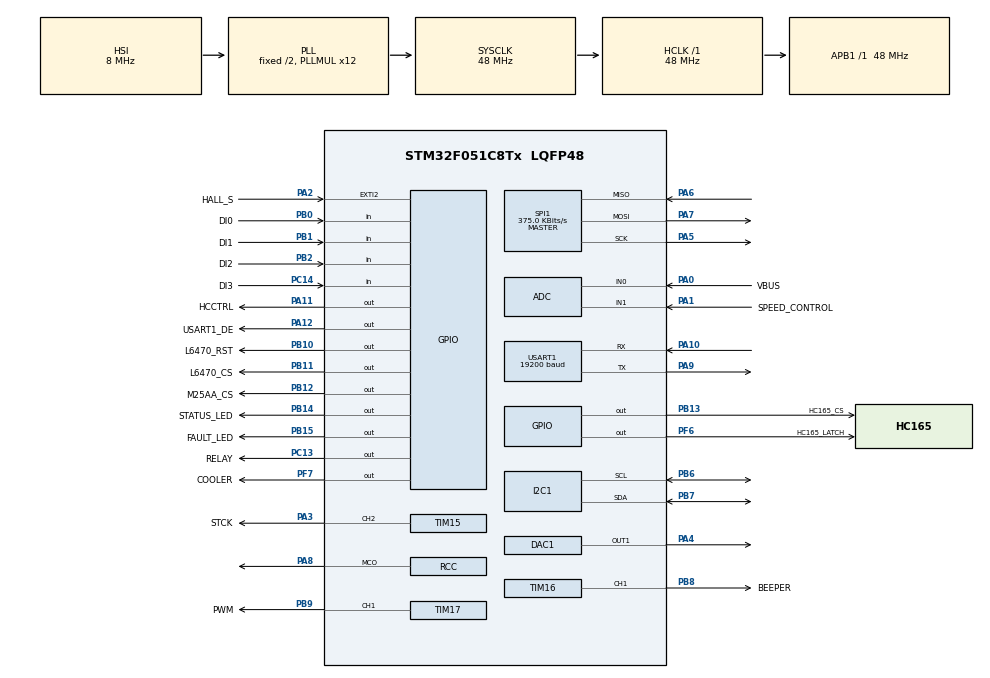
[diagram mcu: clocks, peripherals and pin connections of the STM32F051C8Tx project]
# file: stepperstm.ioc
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ADC.Channel-1\#ChannelRegularConversion=ADC_CHANNEL_1
ADC.Channel-2\#ChannelRegularConversion=ADC_CHANNEL_TEMPSENSOR
ADC.Channel-IN=ADC_CHANNEL_TEMPSENSOR
ADC.Channel-IN1=ADC_CHANNEL_1
ADC.NbrOfConversion=3
ADC.NbrOfConversionFlag=1
ADC.Rank-0\#ChannelRegularConversion=1
ADC.Rank-1\#ChannelRegularConversion=2
ADC.Rank-2\#ChannelRegularConversion=3
ADC.SamplingTime=ADC_SAMPLETIME_13CYCLES_5
ADC.master=1
DAC1.DAC_OutputBuffer-DAC_OUT1=DAC_OUTPUTBUFFER_ENABLE
DAC1.DAC_Trigger-DAC_OUT1=DAC_TRIGGER_NONE
Mcu.Family=STM32F0
Mcu.Name=STM32F051C8Tx
Mcu.Package=LQFP48
Mcu.UserConstants=RS485_DE_HW_ENABLE,0
NVIC.EXTI2_3_IRQn=true\:0\:0\:false\:false\:true\:true
NVIC.TIM6_DAC_IRQn=true\:0\:0\:false\:false\:true\:true
NVIC.USART1_IRQn=true\:0\:0\:false\:false\:true\:true
PA0.GPIO_Label=VBUS
PA0.Mode=IN0
PA0.Signal=ADC_IN0
PA1.GPIO_Label=SPEED_CONTROL
PA1.Mode=IN1
PA1.Signal=ADC_IN1
PA10.GPIO_PuPd=GPIO_NOPULL
PA10.Mode=Asynchronous
PA10.Signal=USART1_RX
PA11.GPIO_Label=HCCTRL
PA11.Signal=GPIO_Output
PA12.GPIO_Label=USART1_DE
PA12.Signal=GPIO_Output
PA13.Mode=Serial_Wire
PA13.Signal=SYS_SWDIO
PA14.Mode=Serial_Wire
PA14.Signal=SYS_SWCLK
PA2.GPIO_Label=HALL_S
PA2.Signal=GPXTI2
PA3.GPIO_Label=STCK
PA3.Signal=S_TIM15_CH2
PA4.Signal=COMP_DAC11_group
PA5.Mode=Full_Duplex_Master
PA5.Signal=SPI1_SCK
PA6.GPIO_PuPd=GPIO_PULLUP
PA6.Mode=Full_Duplex_Master
PA6.Signal=SPI1_MISO
PA7.Mode=Full_Duplex_Master
PA7.Signal=SPI1_MOSI
PA8.Mode=Clock-out
PA8.Signal=RCC_MCO
PA9.GPIO_PuPd=GPIO_NOPULL
PA9.Mode=Asynchronous
PA9.Signal=USART1_TX
PB0.GPIO_Label=DI0
PB0.GPIO_PuPd=GPIO_PULLUP
PB0.Signal=GPIO_Input
PB1.GPIO_Label=DI1
PB1.GPIO_PuPd=GPIO_PULLUP
PB1.Signal=GPIO_Input
PB10.GPIO_Label=L6470_RST
PB10.GPIO_PuPd=GPIO_PULLUP
PB10.PinState=GPIO_PIN_SET
PB10.Signal=GPIO_Output
PB11.GPIO_Label=L6470_CS
PB11.PinState=GPIO_PIN_SET
PB11.Signal=GPIO_Output
PB12.GPIO_Label=M25AA_CS
PB12.PinState=GPIO_PIN_SET
PB12.Signal=GPIO_Output
PB13.GPIO_Label=HC165_CS
PB13.PinState=GPIO_PIN_SET
PB13.Signal=GPIO_Output
PB14.GPIO_Label=STATUS_LED
PB14.GPIO_PuPd=GPIO_PULLUP
PB14.PinState=GPIO_PIN_SET
PB14.Signal=GPIO_Output
PB15.GPIO_Label=FAULT_LED
PB15.GPIO_PuPd=GPIO_PULLUP
PB15.PinState=GPIO_PIN_SET
PB15.Signal=GPIO_Output
PB2.GPIO_Label=DI2
PB2.GPIO_PuPd=GPIO_PULLUP
PB2.Signal=GPIO_Input
PB6.Mode=I2C
PB6.Signal=I2C1_SCL
PB7.Mode=I2C
PB7.Signal=I2C1_SDA
PB8.GPIO_Label=BEEPER
PB8.Signal=S_TIM16_CH1
PB9.GPIO_Label=PWM
PB9.Signal=S_TIM17_CH1
PC13.GPIO_Label=RELAY
PC13.Signal=GPIO_Output
PC14-OSC32_IN.GPIO_Label=DI3
PC14-OSC32_IN.GPIO_PuPd=GPIO_PULLUP
PC14-OSC32_IN.Signal=GPIO_Input
PF0-OSC_IN.Mode=HSE-External-Oscillator
PF0-OSC_IN.Signal=RCC_OSC_IN
PF1-OSC_OUT.Mode=HSE-External-Oscillator
PF1-OSC_OUT.Signal=RCC_OSC_OUT
PF6.GPIO_Label=HC165_LATCH
PF6.PinState=GPIO_PIN_SET
PF6.Signal=GPIO_Output
PF7.GPIO_Label=COOLER
PF7.Signal=GPIO_Output
ProjectManager.HeapSize=0x200
ProjectManager.StackSize=0x400
ProjectManager.TargetToolchain=Other Toolchains (GPDSC)
RCC.AHBFreq_Value=48000000
RCC.APB1Freq_Value=48000000
RCC.APB1TimFreq_Value=48000000
RCC.FLatency=FLASH_LATENCY_1
RCC.HCLKFreq_Value=48000000
RCC.PLLMUL=RCC_PLL_MUL12
RCC.SYSCLKFreq_VALUE=48000000
RCC.SYSCLKSource=RCC_SYSCLKSOURCE_PLLCLK
SH.COMP_DAC11_group.0=DAC1_OUT1,DAC_OUT1
SH.S_TIM15_CH2.0=TIM15_CH2,Output Compare2 CH2
SH.S_TIM16_CH1.0=TIM16_CH1,Output Compare1 CH1
SH.S_TIM17_CH1.0=TIM17_CH1,PWM Generation1 CH1
SPI1.BaudRatePrescaler=SPI_BAUDRATEPRESCALER_128
SPI1.CalculateBaudRate=375.0 KBits/s
SPI1.DataSize=SPI_DATASIZE_8BIT
SPI1.Direction=SPI_DIRECTION_2LINES
SPI1.Mode=SPI_MODE_MASTER
SPI1.VirtualType=VM_MASTER
TIM15.Channel-Output\ Compare2\ CH2=TIM_CHANNEL_2
TIM16.Channel=TIM_CHANNEL_1
TIM16.OCMode_1=TIM_OCMODE_TOGGLE
TIM16.Period=24000
TIM17.Channel=TIM_CHANNEL_1
TIM6.Period=1000
USART1.BaudRate=19200
USART1.VirtualMode-Asynchronous=VM_ASYNC
VP_ADC_TempSens_Input.Mode=IN-TempSens
VP_IWDG_VS_IWDG.Mode=IWDG_Activate
VP_TIM16_VS_ClockSourceINT.Mode=Enable_Timer
VP_TIM17_VS_ClockSourceINT.Mode=Enable_Timer
VP_TIM6_VS_ClockSourceINT.Mode=Enable_Timer
VP_TIM6_VS_OPM.Mode=OPM_bit
board=stepperstm

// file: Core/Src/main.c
/**
  ******************************************************************************
  * @file           : main.c
  * @brief          : Main program body
  ******************************************************************************
  ** This notice applies to any and all portions of this file
  * that are not between comment pairs USER CODE BEGIN and
  * USER CODE END. Other portions of this file, whether
  * inserted by the user or by software development tools
  * are owned by their respective copyright owners.
  *
  * COPYRIGHT(c) 2018 STMicroelectronics
  *
  * Redistribution and use in source and binary forms, with or without modification,
  * are permitted provided that the following conditions are met:
  *   1. Redistributions of source code must retain the above copyright notice,
  *      this list of conditions and the following disclaimer.
  *   2. Redistributions in binary form must reproduce the above copyright notice,
  *      this list of conditions and the following disclaimer in the documentation
  *      and/or other materials provided with the distribution.
  *   3. Neither the name of STMicroelectronics nor the names of its contributors
  *      may be used to endorse or promote products derived from this software
  *      without specific prior written permission.
  *
  * THIS SOFTWARE IS PROVIDED BY THE COPYRIGHT HOLDERS AND CONTRIBUTORS "AS IS"
  * AND ANY EXPRESS OR IMPLIED WARRANTIES, INCLUDING, BUT NOT LIMITED TO, THE
  * IMPLIED WARRANTIES OF MERCHANTABILITY AND FITNESS FOR A PARTICULAR PURPOSE ARE
  * DISCLAIMED. IN NO EVENT SHALL THE COPYRIGHT HOLDER OR CONTRIBUTORS BE LIABLE
  * FOR ANY DIRECT, INDIRECT, INCIDENTAL, SPECIAL, EXEMPLARY, OR CONSEQUENTIAL
  * DAMAGES (INCLUDING, BUT NOT LIMITED TO, PROCUREMENT OF SUBSTITUTE GOODS OR
  * SERVICES; LOSS OF USE, DATA, OR PROFITS; OR BUSINESS INTERRUPTION) HOWEVER
  * CAUSED AND ON ANY THEORY OF LIABILITY, WHETHER IN CONTRACT, STRICT LIABILITY,
  * OR TORT (INCLUDING NEGLIGENCE OR OTHERWISE) ARISING IN ANY WAY OUT OF THE USE
  * OF THIS SOFTWARE, EVEN IF ADVISED OF THE POSSIBILITY OF SUCH DAMAGE.
  *
  ******************************************************************************
  */
#include "main.h"
#include "stm32f0xx_hal.h"

ADC_HandleTypeDef hadc;

DAC_HandleTypeDef hdac1;

I2C_HandleTypeDef hi2c1;

IWDG_HandleTypeDef hiwdg;

SPI_HandleTypeDef hspi1;

TIM_HandleTypeDef htim6;
TIM_HandleTypeDef htim15;
TIM_HandleTypeDef htim16;
TIM_HandleTypeDef htim17;

UART_HandleTypeDef huart1;

/* USER CODE BEGIN PV */
UART_HandleTypeDef* pMbPort = &huart1;
TIM_HandleTypeDef* pMbPortTimer = &htim6;
TIM_HandleTypeDef* pBeeperTimer = &htim16;
TIM_HandleTypeDef* pPwmTimer = &htim17;

/* Private variables ---------------------------------------------------------*/
/* USER CODE END PV */

void SystemClock_Config(void);
static void MX_GPIO_Init(void);
static void MX_ADC_Init(void);
static void MX_DAC1_Init(void);
static void MX_IWDG_Init(void);
static void MX_TIM6_Init(void);
static void MX_I2C1_Init(void);
static void MX_TIM15_Init(void);
static void MX_TIM17_Init(void);
static void MX_USART1_UART_Init(void);
static void MX_TIM16_Init(void);
static void MX_SPI1_Init(void);

void HAL_TIM_MspPostInit(TIM_HandleTypeDef *htim);

/* USER CODE BEGIN PFP */
/* -----------------------------Extern functions ---------------------------- */
/* ------------------------ Private function prototypes ----------------------*/

/* USER CODE END PFP */

int main(void)
{

  /* MCU Configuration----------------------------------------------------------*/

  /* Reset of all peripherals, Initializes the Flash interface and the Systick. */
  HAL_Init();

  /* Configure the system clock */
  SystemClock_Config();

  /* Initialize all configured peripherals */
  MX_GPIO_Init();
  MX_ADC_Init();
  MX_DAC1_Init();
  MX_IWDG_Init();
  MX_TIM6_Init();
  MX_I2C1_Init();
  MX_TIM15_Init();
  MX_TIM17_Init();
  MX_USART1_UART_Init();
  MX_TIM16_Init();
  MX_SPI1_Init();

  /* Infinite loop */
  while (1)
  {

  }

}

void SystemClock_Config(void)
{

  RCC_OscInitTypeDef RCC_OscInitStruct;
  RCC_ClkInitTypeDef RCC_ClkInitStruct;
  RCC_PeriphCLKInitTypeDef PeriphClkInit;

    /**Initializes the CPU, AHB and APB busses clocks
    */
  RCC_OscInitStruct.OscillatorType = RCC_OSCILLATORTYPE_HSI|RCC_OSCILLATORTYPE_HSI14
                              |RCC_OSCILLATORTYPE_LSI;
  RCC_OscInitStruct.HSIState = RCC_HSI_ON;
  RCC_OscInitStruct.HSI14State = RCC_HSI14_ON;
  RCC_OscInitStruct.HSICalibrationValue = 16;
  RCC_OscInitStruct.HSI14CalibrationValue = 16;
  RCC_OscInitStruct.LSIState = RCC_LSI_ON;
  RCC_OscInitStruct.PLL.PLLState = RCC_PLL_ON;
  RCC_OscInitStruct.PLL.PLLSource = RCC_PLLSOURCE_HSI;
  RCC_OscInitStruct.PLL.PLLMUL = RCC_PLL_MUL12;
  RCC_OscInitStruct.PLL.PREDIV = RCC_PREDIV_DIV1;
  if (HAL_RCC_OscConfig(&RCC_OscInitStruct) != HAL_OK)
  {
    _Error_Handler(__FILE__, __LINE__);
  }

    /**Initializes the CPU, AHB and APB busses clocks
    */
  RCC_ClkInitStruct.ClockType = RCC_CLOCKTYPE_HCLK|RCC_CLOCKTYPE_SYSCLK
                              |RCC_CLOCKTYPE_PCLK1;
  RCC_ClkInitStruct.SYSCLKSource = RCC_SYSCLKSOURCE_PLLCLK;
  RCC_ClkInitStruct.AHBCLKDivider = RCC_SYSCLK_DIV1;
  RCC_ClkInitStruct.APB1CLKDivider = RCC_HCLK_DIV1;

  if (HAL_RCC_ClockConfig(&RCC_ClkInitStruct, FLASH_LATENCY_1) != HAL_OK)
  {
    _Error_Handler(__FILE__, __LINE__);
  }

  PeriphClkInit.PeriphClockSelection = RCC_PERIPHCLK_USART1|RCC_PERIPHCLK_I2C1;
  PeriphClkInit.Usart1ClockSelection = RCC_USART1CLKSOURCE_PCLK1;
  PeriphClkInit.I2c1ClockSelection = RCC_I2C1CLKSOURCE_HSI;
  if (HAL_RCCEx_PeriphCLKConfig(&PeriphClkInit) != HAL_OK)
  {
    _Error_Handler(__FILE__, __LINE__);
  }

  HAL_RCC_MCOConfig(RCC_MCO, RCC_MCO1SOURCE_SYSCLK, RCC_MCODIV_1);

    /**Configure the Systick interrupt time
    */
  HAL_SYSTICK_Config(HAL_RCC_GetHCLKFreq()/1000);

    /**Configure the Systick
    */
  HAL_SYSTICK_CLKSourceConfig(SYSTICK_CLKSOURCE_HCLK);

  /* SysTick_IRQn interrupt configuration */
  HAL_NVIC_SetPriority(SysTick_IRQn, 0, 0);
}

/* ADC init function */
static void MX_ADC_Init(void)
{

  ADC_ChannelConfTypeDef sConfig;

    /**Configure the global features of the ADC (Clock, Resolution, Data Alignment and number of conversion)
    */
  hadc.Instance = ADC1;
  hadc.Init.ClockPrescaler = ADC_CLOCK_ASYNC_DIV1;
  hadc.Init.Resolution = ADC_RESOLUTION_12B;
  hadc.Init.DataAlign = ADC_DATAALIGN_RIGHT;
  hadc.Init.ScanConvMode = ADC_SCAN_DIRECTION_FORWARD;
  hadc.Init.EOCSelection = ADC_EOC_SINGLE_CONV;
  hadc.Init.LowPowerAutoWait = DISABLE;
  hadc.Init.LowPowerAutoPowerOff = DISABLE;
  hadc.Init.ContinuousConvMode = DISABLE;
  hadc.Init.DiscontinuousConvMode = DISABLE;
  hadc.Init.ExternalTrigConv = ADC_SOFTWARE_START;
  hadc.Init.ExternalTrigConvEdge = ADC_EXTERNALTRIGCONVEDGE_NONE;
  hadc.Init.DMAContinuousRequests = DISABLE;
  hadc.Init.Overrun = ADC_OVR_DATA_PRESERVED;
  if (HAL_ADC_Init(&hadc) != HAL_OK)
  {
    _Error_Handler(__FILE__, __LINE__);
  }

    /**Configure for the selected ADC regular channel to be converted.
    */
  sConfig.Channel = ADC_CHANNEL_0;
  sConfig.Rank = ADC_RANK_CHANNEL_NUMBER;
  sConfig.SamplingTime = ADC_SAMPLETIME_13CYCLES_5;
  if (HAL_ADC_ConfigChannel(&hadc, &sConfig) != HAL_OK)
  {
    _Error_Handler(__FILE__, __LINE__);
  }

    /**Configure for the selected ADC regular channel to be converted.
    */
  sConfig.Channel = ADC_CHANNEL_1;
  if (HAL_ADC_ConfigChannel(&hadc, &sConfig) != HAL_OK)
  {
    _Error_Handler(__FILE__, __LINE__);
  }

    /**Configure for the selected ADC regular channel to be converted.
    */
  sConfig.Channel = ADC_CHANNEL_TEMPSENSOR;
  if (HAL_ADC_ConfigChannel(&hadc, &sConfig) != HAL_OK)
  {
    _Error_Handler(__FILE__, __LINE__);
  }

}

/* DAC1 init function */
static void MX_DAC1_Init(void)
{

  DAC_ChannelConfTypeDef sConfig;

    /**DAC Initialization
    */
  hdac1.Instance = DAC;
  if (HAL_DAC_Init(&hdac1) != HAL_OK)
  {
    _Error_Handler(__FILE__, __LINE__);
  }

    /**DAC channel OUT1 config
    */
  sConfig.DAC_Trigger = DAC_TRIGGER_NONE;
  sConfig.DAC_OutputBuffer = DAC_OUTPUTBUFFER_ENABLE;
  if (HAL_DAC_ConfigChannel(&hdac1, &sConfig, DAC_CHANNEL_1) != HAL_OK)
  {
    _Error_Handler(__FILE__, __LINE__);
  }

}

/* I2C1 init function */
static void MX_I2C1_Init(void)
{

  hi2c1.Instance = I2C1;
  hi2c1.Init.Timing = 0x2000090E;
  hi2c1.Init.OwnAddress1 = 0;
  hi2c1.Init.AddressingMode = I2C_ADDRESSINGMODE_7BIT;
  hi2c1.Init.DualAddressMode = I2C_DUALADDRESS_DISABLE;
  hi2c1.Init.OwnAddress2 = 0;
  hi2c1.Init.OwnAddress2Masks = I2C_OA2_NOMASK;
  hi2c1.Init.GeneralCallMode = I2C_GENERALCALL_DISABLE;
  hi2c1.Init.NoStretchMode = I2C_NOSTRETCH_DISABLE;
  if (HAL_I2C_Init(&hi2c1) != HAL_OK)
  {
    _Error_Handler(__FILE__, __LINE__);
  }

    /**Configure Analogue filter
    */
  if (HAL_I2CEx_ConfigAnalogFilter(&hi2c1, I2C_ANALOGFILTER_ENABLE) != HAL_OK)
  {
    _Error_Handler(__FILE__, __LINE__);
  }

    /**Configure Digital filter
    */
  if (HAL_I2CEx_ConfigDigitalFilter(&hi2c1, 0) != HAL_OK)
  {
    _Error_Handler(__FILE__, __LINE__);
  }

}

/* IWDG init function */
static void MX_IWDG_Init(void)
{

  hiwdg.Instance = IWDG;
  hiwdg.Init.Prescaler = IWDG_PRESCALER_4;
  hiwdg.Init.Window = 4095;
  hiwdg.Init.Reload = 4095;
  if (HAL_IWDG_Init(&hiwdg) != HAL_OK)
  {
    _Error_Handler(__FILE__, __LINE__);
  }

}

/* SPI1 init function */
static void MX_SPI1_Init(void)
{

  /* SPI1 parameter configuration*/
  hspi1.Instance = SPI1;
  hspi1.Init.Mode = SPI_MODE_MASTER;
  hspi1.Init.Direction = SPI_DIRECTION_2LINES;
  hspi1.Init.DataSize = SPI_DATASIZE_8BIT;
  hspi1.Init.CLKPolarity = SPI_POLARITY_LOW;
  hspi1.Init.CLKPhase = SPI_PHASE_1EDGE;
  hspi1.Init.NSS = SPI_NSS_SOFT;
  hspi1.Init.BaudRatePrescaler = SPI_BAUDRATEPRESCALER_128;
  hspi1.Init.FirstBit = SPI_FIRSTBIT_MSB;
  hspi1.Init.TIMode = SPI_TIMODE_DISABLE;
  hspi1.Init.CRCCalculation = SPI_CRCCALCULATION_DISABLE;
  hspi1.Init.CRCPolynomial = 7;
  hspi1.Init.CRCLength = SPI_CRC_LENGTH_DATASIZE;
  hspi1.Init.NSSPMode = SPI_NSS_PULSE_ENABLE;
  if (HAL_SPI_Init(&hspi1) != HAL_OK)
  {
    _Error_Handler(__FILE__, __LINE__);
  }

}

/* TIM6 init function */
static void MX_TIM6_Init(void)
{

  TIM_MasterConfigTypeDef sMasterConfig;

  htim6.Instance = TIM6;
  htim6.Init.Prescaler = 0;
  htim6.Init.CounterMode = TIM_COUNTERMODE_UP;
  htim6.Init.Period = 1000;
  htim6.Init.AutoReloadPreload = TIM_AUTORELOAD_PRELOAD_DISABLE;
  if (HAL_TIM_Base_Init(&htim6) != HAL_OK)
  {
    _Error_Handler(__FILE__, __LINE__);
  }

  if (HAL_TIM_OnePulse_Init(&htim6, TIM_OPMODE_SINGLE) != HAL_OK)
  {
    _Error_Handler(__FILE__, __LINE__);
  }

  sMasterConfig.MasterOutputTrigger = TIM_TRGO_RESET;
  sMasterConfig.MasterSlaveMode = TIM_MASTERSLAVEMODE_DISABLE;
  if (HAL_TIMEx_MasterConfigSynchronization(&htim6, &sMasterConfig) != HAL_OK)
  {
    _Error_Handler(__FILE__, __LINE__);
  }

}

/* TIM15 init function */
static void MX_TIM15_Init(void)
{

  TIM_MasterConfigTypeDef sMasterConfig;
  TIM_OC_InitTypeDef sConfigOC;
  TIM_BreakDeadTimeConfigTypeDef sBreakDeadTimeConfig;

  htim15.Instance = TIM15;
  htim15.Init.Prescaler = 0;
  htim15.Init.CounterMode = TIM_COUNTERMODE_UP;
  htim15.Init.Period = 0;
  htim15.Init.ClockDivision = TIM_CLOCKDIVISION_DIV1;
  htim15.Init.RepetitionCounter = 0;
  htim15.Init.AutoReloadPreload = TIM_AUTORELOAD_PRELOAD_DISABLE;
  if (HAL_TIM_OC_Init(&htim15) != HAL_OK)
  {
    _Error_Handler(__FILE__, __LINE__);
  }

  sMasterConfig.MasterOutputTrigger = TIM_TRGO_RESET;
  sMasterConfig.MasterSlaveMode = TIM_MASTERSLAVEMODE_DISABLE;
  if (HAL_TIMEx_MasterConfigSynchronization(&htim15, &sMasterConfig) != HAL_OK)
  {
    _Error_Handler(__FILE__, __LINE__);
  }

  sConfigOC.OCMode = TIM_OCMODE_TIMING;
  sConfigOC.Pulse = 0;
  sConfigOC.OCPolarity = TIM_OCPOLARITY_HIGH;
  sConfigOC.OCNPolarity = TIM_OCNPOLARITY_HIGH;
  sConfigOC.OCFastMode = TIM_OCFAST_DISABLE;
  sConfigOC.OCIdleState = TIM_OCIDLESTATE_RESET;
  sConfigOC.OCNIdleState = TIM_OCNIDLESTATE_RESET;
  if (HAL_TIM_OC_ConfigChannel(&htim15, &sConfigOC, TIM_CHANNEL_2) != HAL_OK)
  {
    _Error_Handler(__FILE__, __LINE__);
  }

  sBreakDeadTimeConfig.OffStateRunMode = TIM_OSSR_DISABLE;
  sBreakDeadTimeConfig.OffStateIDLEMode = TIM_OSSI_DISABLE;
  sBreakDeadTimeConfig.LockLevel = TIM_LOCKLEVEL_OFF;
  sBreakDeadTimeConfig.DeadTime = 0;
  sBreakDeadTimeConfig.BreakState = TIM_BREAK_DISABLE;
  sBreakDeadTimeConfig.BreakPolarity = TIM_BREAKPOLARITY_HIGH;
  sBreakDeadTimeConfig.AutomaticOutput = TIM_AUTOMATICOUTPUT_DISABLE;
  if (HAL_TIMEx_ConfigBreakDeadTime(&htim15, &sBreakDeadTimeConfig) != HAL_OK)
  {
    _Error_Handler(__FILE__, __LINE__);
  }

  HAL_TIM_MspPostInit(&htim15);

}

/* TIM16 init function */
static void MX_TIM16_Init(void)
{

  TIM_OC_InitTypeDef sConfigOC;
  TIM_BreakDeadTimeConfigTypeDef sBreakDeadTimeConfig;

  htim16.Instance = TIM16;
  htim16.Init.Prescaler = 0;
  htim16.Init.CounterMode = TIM_COUNTERMODE_UP;
  htim16.Init.Period = 24000;
  htim16.Init.ClockDivision = TIM_CLOCKDIVISION_DIV1;
  htim16.Init.RepetitionCounter = 0;
  htim16.Init.AutoReloadPreload = TIM_AUTORELOAD_PRELOAD_DISABLE;
  if (HAL_TIM_Base_Init(&htim16) != HAL_OK)
  {
    _Error_Handler(__FILE__, __LINE__);
  }

  if (HAL_TIM_OC_Init(&htim16) != HAL_OK)
  {
    _Error_Handler(__FILE__, __LINE__);
  }

  sConfigOC.OCMode = TIM_OCMODE_TOGGLE;
  sConfigOC.Pulse = 0;
  sConfigOC.OCPolarity = TIM_OCPOLARITY_HIGH;
  sConfigOC.OCNPolarity = TIM_OCNPOLARITY_HIGH;
  sConfigOC.OCFastMode = TIM_OCFAST_DISABLE;
  sConfigOC.OCIdleState = TIM_OCIDLESTATE_RESET;
  sConfigOC.OCNIdleState = TIM_OCNIDLESTATE_RESET;
  if (HAL_TIM_OC_ConfigChannel(&htim16, &sConfigOC, TIM_CHANNEL_1) != HAL_OK)
  {
    _Error_Handler(__FILE__, __LINE__);
  }

  sBreakDeadTimeConfig.OffStateRunMode = TIM_OSSR_DISABLE;
  sBreakDeadTimeConfig.OffStateIDLEMode = TIM_OSSI_DISABLE;
  sBreakDeadTimeConfig.LockLevel = TIM_LOCKLEVEL_OFF;
  sBreakDeadTimeConfig.DeadTime = 0;
  sBreakDeadTimeConfig.BreakState = TIM_BREAK_DISABLE;
  sBreakDeadTimeConfig.BreakPolarity = TIM_BREAKPOLARITY_HIGH;
  sBreakDeadTimeConfig.AutomaticOutput = TIM_AUTOMATICOUTPUT_DISABLE;
  if (HAL_TIMEx_ConfigBreakDeadTime(&htim16, &sBreakDeadTimeConfig) != HAL_OK)
  {
    _Error_Handler(__FILE__, __LINE__);
  }

  HAL_TIM_MspPostInit(&htim16);

}

/* TIM17 init function */
static void MX_TIM17_Init(void)
{

  TIM_OC_InitTypeDef sConfigOC;
  TIM_BreakDeadTimeConfigTypeDef sBreakDeadTimeConfig;

  htim17.Instance = TIM17;
  htim17.Init.Prescaler = 0;
  htim17.Init.CounterMode = TIM_COUNTERMODE_UP;
  htim17.Init.Period = 0;
  htim17.Init.ClockDivision = TIM_CLOCKDIVISION_DIV1;
  htim17.Init.RepetitionCounter = 0;
  htim17.Init.AutoReloadPreload = TIM_AUTORELOAD_PRELOAD_DISABLE;
  if (HAL_TIM_Base_Init(&htim17) != HAL_OK)
  {
    _Error_Handler(__FILE__, __LINE__);
  }

  if (HAL_TIM_PWM_Init(&htim17) != HAL_OK)
  {
    _Error_Handler(__FILE__, __LINE__);
  }

  sConfigOC.OCMode = TIM_OCMODE_PWM1;
  sConfigOC.Pulse = 0;
  sConfigOC.OCPolarity = TIM_OCPOLARITY_HIGH;
  sConfigOC.OCNPolarity = TIM_OCNPOLARITY_HIGH;
  sConfigOC.OCFastMode = TIM_OCFAST_DISABLE;
  sConfigOC.OCIdleState = TIM_OCIDLESTATE_RESET;
  sConfigOC.OCNIdleState = TIM_OCNIDLESTATE_RESET;
  if (HAL_TIM_PWM_ConfigChannel(&htim17, &sConfigOC, TIM_CHANNEL_1) != HAL_OK)
  {
    _Error_Handler(__FILE__, __LINE__);
  }

  sBreakDeadTimeConfig.OffStateRunMode = TIM_OSSR_DISABLE;
  sBreakDeadTimeConfig.OffStateIDLEMode = TIM_OSSI_DISABLE;
  sBreakDeadTimeConfig.LockLevel = TIM_LOCKLEVEL_OFF;
  sBreakDeadTimeConfig.DeadTime = 0;
  sBreakDeadTimeConfig.BreakState = TIM_BREAK_DISABLE;
  sBreakDeadTimeConfig.BreakPolarity = TIM_BREAKPOLARITY_HIGH;
  sBreakDeadTimeConfig.AutomaticOutput = TIM_AUTOMATICOUTPUT_DISABLE;
  if (HAL_TIMEx_ConfigBreakDeadTime(&htim17, &sBreakDeadTimeConfig) != HAL_OK)
  {
    _Error_Handler(__FILE__, __LINE__);
  }

  HAL_TIM_MspPostInit(&htim17);

}

/* USART1 init function */
static void MX_USART1_UART_Init(void)
{

  huart1.Instance = USART1;
  huart1.Init.BaudRate = 19200;
  huart1.Init.WordLength = UART_WORDLENGTH_8B;
  huart1.Init.StopBits = UART_STOPBITS_1;
  huart1.Init.Parity = UART_PARITY_NONE;
  huart1.Init.Mode = UART_MODE_TX_RX;
  huart1.Init.HwFlowCtl = UART_HWCONTROL_NONE;
  huart1.Init.OverSampling = UART_OVERSAMPLING_16;
  huart1.Init.OneBitSampling = UART_ONE_BIT_SAMPLE_DISABLE;
  huart1.AdvancedInit.AdvFeatureInit = UART_ADVFEATURE_NO_INIT;
  if (HAL_UART_Init(&huart1) != HAL_OK)
  {
    _Error_Handler(__FILE__, __LINE__);
  }

}

/** Configure pins as
        * Analog
        * Input
        * Output
        * EVENT_OUT
        * EXTI
     PA8   ------> RCC_MCO
*/
static void MX_GPIO_Init(void)
{

  GPIO_InitTypeDef GPIO_InitStruct;

  /* GPIO Ports Clock Enable */
  __HAL_RCC_GPIOC_CLK_ENABLE();
  __HAL_RCC_GPIOF_CLK_ENABLE();
  __HAL_RCC_GPIOA_CLK_ENABLE();
  __HAL_RCC_GPIOB_CLK_ENABLE();

  /*Configure GPIO pin Output Level */
  HAL_GPIO_WritePin(RELAY_GPIO_Port, RELAY_Pin, GPIO_PIN_RESET);

  /*Configure GPIO pin Output Level */
  HAL_GPIO_WritePin(GPIOB, L6470_RST_Pin|L6470_CS_Pin|M25AA_CS_Pin|HC165_CS_Pin
                          |STATUS_LED_Pin|FAULT_LED_Pin, GPIO_PIN_SET);

  /*Configure GPIO pin Output Level */
  HAL_GPIO_WritePin(GPIOA, HCCTRL_Pin|USART1_DE_Pin, GPIO_PIN_RESET);

  /*Configure GPIO pin Output Level */
  HAL_GPIO_WritePin(HC165_LATCH_GPIO_Port, HC165_LATCH_Pin, GPIO_PIN_SET);

  /*Configure GPIO pin Output Level */
  HAL_GPIO_WritePin(COOLER_GPIO_Port, COOLER_Pin, GPIO_PIN_RESET);

  /*Configure GPIO pin : RELAY_Pin */
  GPIO_InitStruct.Pin = RELAY_Pin;
  GPIO_InitStruct.Mode = GPIO_MODE_OUTPUT_PP;
  GPIO_InitStruct.Pull = GPIO_NOPULL;
  GPIO_InitStruct.Speed = GPIO_SPEED_FREQ_LOW;
  HAL_GPIO_Init(RELAY_GPIO_Port, &GPIO_InitStruct);

  /*Configure GPIO pin : DI3_Pin */
  GPIO_InitStruct.Pin = DI3_Pin;
  GPIO_InitStruct.Mode = GPIO_MODE_INPUT;
  GPIO_InitStruct.Pull = GPIO_PULLUP;
  HAL_GPIO_Init(DI3_GPIO_Port, &GPIO_InitStruct);

  /*Configure GPIO pin : HALL_S_Pin */
  GPIO_InitStruct.Pin = HALL_S_Pin;
  GPIO_InitStruct.Mode = GPIO_MODE_IT_RISING;
  GPIO_InitStruct.Pull = GPIO_NOPULL;
  HAL_GPIO_Init(HALL_S_GPIO_Port, &GPIO_InitStruct);

  /*Configure GPIO pins : DI0_Pin DI1_Pin DI2_Pin */
  GPIO_InitStruct.Pin = DI0_Pin|DI1_Pin|DI2_Pin;
  GPIO_InitStruct.Mode = GPIO_MODE_INPUT;
  GPIO_InitStruct.Pull = GPIO_PULLUP;
  HAL_GPIO_Init(GPIOB, &GPIO_InitStruct);

  /*Configure GPIO pins : L6470_RST_Pin STATUS_LED_Pin FAULT_LED_Pin */
  GPIO_InitStruct.Pin = L6470_RST_Pin|STATUS_LED_Pin|FAULT_LED_Pin;
  GPIO_InitStruct.Mode = GPIO_MODE_OUTPUT_PP;
  GPIO_InitStruct.Pull = GPIO_PULLUP;
  GPIO_InitStruct.Speed = GPIO_SPEED_FREQ_LOW;
  HAL_GPIO_Init(GPIOB, &GPIO_InitStruct);

  /*Configure GPIO pins : L6470_CS_Pin M25AA_CS_Pin HC165_CS_Pin */
  GPIO_InitStruct.Pin = L6470_CS_Pin|M25AA_CS_Pin|HC165_CS_Pin;
  GPIO_InitStruct.Mode = GPIO_MODE_OUTPUT_PP;
  GPIO_InitStruct.Pull = GPIO_NOPULL;
  GPIO_InitStruct.Speed = GPIO_SPEED_FREQ_LOW;
  HAL_GPIO_Init(GPIOB, &GPIO_InitStruct);

  /*Configure GPIO pin : PA8 */
  GPIO_InitStruct.Pin = GPIO_PIN_8;
  GPIO_InitStruct.Mode = GPIO_MODE_AF_PP;
  GPIO_InitStruct.Pull = GPIO_NOPULL;
  GPIO_InitStruct.Speed = GPIO_SPEED_FREQ_LOW;
  GPIO_InitStruct.Alternate = GPIO_AF0_MCO;
  HAL_GPIO_Init(GPIOA, &GPIO_InitStruct);

  /*Configure GPIO pins : HCCTRL_Pin USART1_DE_Pin */
  GPIO_InitStruct.Pin = HCCTRL_Pin|USART1_DE_Pin;
  GPIO_InitStruct.Mode = GPIO_MODE_OUTPUT_PP;
  GPIO_InitStruct.Pull = GPIO_NOPULL;
  GPIO_InitStruct.Speed = GPIO_SPEED_FREQ_LOW;
  HAL_GPIO_Init(GPIOA, &GPIO_InitStruct);

  /*Configure GPIO pins : HC165_LATCH_Pin COOLER_Pin */
  GPIO_InitStruct.Pin = HC165_LATCH_Pin|COOLER_Pin;
  GPIO_InitStruct.Mode = GPIO_MODE_OUTPUT_PP;
  GPIO_InitStruct.Pull = GPIO_NOPULL;
  GPIO_InitStruct.Speed = GPIO_SPEED_FREQ_LOW;
  HAL_GPIO_Init(GPIOF, &GPIO_InitStruct);

  /* EXTI interrupt init*/
  HAL_NVIC_SetPriority(EXTI2_3_IRQn, 0, 0);
  HAL_NVIC_EnableIRQ(EXTI2_3_IRQn);

}

/* USER CODE BEGIN 4 */

/* chekinam bodreito reiksme - ar standartine? */
bool SMC_CheckBaudrateValue(uint16_t baudrate){

    const uint32_t baudrates[6U] = { 4800U, 9600U, 19200U, 38400U, 57600U };
    uint8_t i = 0;

    while( baudrate != baudrates[i++] ) {
        if( i >= ( sizeof(baudrates)/sizeof(baudrate) ) ) return false;
    }

    return true;
}
/* USER CODE END 4 */

void _Error_Handler(char *file, int line)
{
  while(1)
  {
  }
}

/************************ (C) COPYRIGHT STMicroelectronics *****END OF FILE****/
